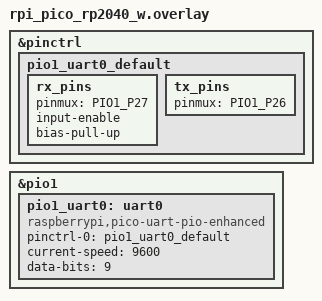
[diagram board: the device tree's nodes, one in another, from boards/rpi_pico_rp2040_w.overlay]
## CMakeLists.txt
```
# SPDX-License-Identifier: Apache-2.0
# Copyright (c) 2025 Blue Vending

cmake_minimum_required(VERSION 3.20.0)
find_package(Zephyr REQUIRED HINTS $ENV{ZEPHYR_BASE})

project(uart_pio_test)

# Include the main application source
target_sources(app PRIVATE src/main.c)
```

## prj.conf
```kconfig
# SPDX-License-Identifier: Apache-2.0
# Copyright (c) 2025 Blue Vending

# Enable PIO UART driver
CONFIG_UART_RPI_PICO_PIO_ENHANCED=y
CONFIG_UART_ASYNC_API=y

# UART subsystem
CONFIG_SERIAL=y
CONFIG_UART_CONSOLE=y
CONFIG_CONSOLE=y

# Logging
CONFIG_LOG=y
CONFIG_LOG_DEFAULT_LEVEL=3
CONFIG_LOG_MODE_IMMEDIATE=y
CONFIG_UART_RPI_PICO_PIO_ENHANCED_LOG_LEVEL=4

# PIO subsystem
CONFIG_PIO_RPI_PICO=y

# GPIO for pin configuration
CONFIG_GPIO=y

# Pinctrl subsystem
CONFIG_PINCTRL=y

# Kernel options
CONFIG_MAIN_STACK_SIZE=2048
CONFIG_SYSTEM_WORKQUEUE_STACK_SIZE=2048

# Enable printk for debugging
CONFIG_PRINTK=y
CONFIG_EARLY_CONSOLE=y
```

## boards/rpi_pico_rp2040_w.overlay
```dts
/*
 * Copyright (c) 2025 Blue Vending
 *
 * SPDX-License-Identifier: Apache-2.0
 */

&pinctrl {
	pio1_uart0_default: pio1_uart0_default {
		rx_pins {
			pinmux = <PIO1_P27>;
			input-enable;
			bias-pull-up;
		};
		tx_pins {
			pinmux = <PIO1_P26>;
		};
	};
};

&pio1 {
	status = "okay";

	pio1_uart0: uart0 {
		pinctrl-0 = <&pio1_uart0_default>;
		pinctrl-names = "default";

		compatible = "raspberrypi,pico-uart-pio-enhanced";
		current-speed = <9600>;
		data-bits = <9>;
		status = "okay";
	};
};
```

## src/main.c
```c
/*
 * Copyright (c) 2025 Blue Vending
 *
 * SPDX-License-Identifier: Apache-2.0
 */

#include <zephyr/kernel.h>
#include <zephyr/drivers/uart.h>
#include <zephyr/device.h>
#include <zephyr/logging/log.h>
#include <string.h>

LOG_MODULE_REGISTER(uart_pio_test, LOG_LEVEL_DBG);

/* Get the PIO UART device */
#define PIO_UART_NODE DT_NODELABEL(pio1_uart0)
static const struct device *const pio_uart_device = DEVICE_DT_GET(PIO_UART_NODE);

/* Test data */
static char rx_buffer[256];
static size_t rx_count;

void uart_irq_callback(const struct device *dev, void *user_data)
{
	uint16_t c;
	ARG_UNUSED(user_data);

	if (uart_poll_in_u16(dev, &c) != 0) {
		return;
	}
	printk("%X\n", c);
}

int main(void)
{
	LOG_INF("PIO UART Test Application Starting");

	/* Check if device is ready */
	if (!device_is_ready(pio_uart_device)) {
		LOG_ERR("PIO UART device not ready");
		return -1;
	}

	LOG_INF("PIO UART device is ready");
	uart_irq_callback_set(pio_uart_device, uart_irq_callback);
	uart_irq_rx_enable(pio_uart_device);
	/* Keep running for continuous testing */
	while (1) {
		// read via polling
		uint16_t c;

		k_sleep(K_MSEC(100));
	}

	return 0;
}
```

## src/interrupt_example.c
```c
/*
 * Copyright (c) 2025 Blue Vending
 *
 * SPDX-License-Identifier: Apache-2.0
 */

#include <zephyr/kernel.h>
#include <zephyr/device.h>
#include <zephyr/drivers/uart.h>
#include <zephyr/sys/printk.h>

#define UART_DEVICE_NODE DT_NODELABEL(pio1_uart0)

static const struct device *const uart_dev = DEVICE_DT_GET(UART_DEVICE_NODE);

/* Buffer for incoming data */
static char rx_buffer[128];
static int rx_index = 0;

/* UART interrupt callback */
static void uart_irq_callback(const struct device *dev, void *user_data)
{
	unsigned char c;

	/* Check if we have received data */
	if (uart_irq_rx_ready(dev)) {
		/* Read all available characters */
		while (uart_poll_in(dev, &c) == 0) {
			if (rx_index < sizeof(rx_buffer) - 1) {
				rx_buffer[rx_index++] = c;

				/* Echo the character back */
				uart_poll_out(dev, c);

				/* Check for newline to process the command */
				if (c == '\n' || c == '\r') {
					rx_buffer[rx_index] = '\0';
					printk("Received: %s", rx_buffer);
					rx_index = 0;
				}
			}
		}
	}
}

int main(void)
{
	int ret;

	printk("PIO UART Interrupt Example\n");

	if (!device_is_ready(uart_dev)) {
		printk("UART device not ready\n");
		return -1;
	}

	/* Set up interrupt callback */
	uart_irq_callback_user_data_set(uart_dev, uart_irq_callback, NULL);

	/* Enable RX interrupts */
	uart_irq_rx_enable(uart_dev);

	printk("UART interrupts enabled. Type something and press Enter:\n");

	/* Send a test message */
	const char *test_msg = "Hello from PIO UART with interrupts!\n";
	for (int i = 0; test_msg[i]; i++) {
		uart_poll_out(uart_dev, test_msg[i]);
	}

	/* Main loop - the real work is done in interrupt handler */
	while (1) {
		k_sleep(K_MSEC(1000));
		printk("Heartbeat - waiting for UART data...\n");
	}

	return 0;
}
```
